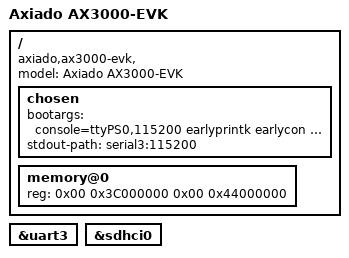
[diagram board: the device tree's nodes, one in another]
// SPDX-License-Identifier: GPL-2.0+
/*
 * Copyright (c) 2021-25 Axiado Corporation (or its affiliates).
 */

/dts-v1/;

#include "ax3000.dtsi"

/ {
	model = "Axiado AX3000-EVK";
	compatible = "axiado,ax3000-evk,", "axiado, ax3000";
	#address-cells = <2>;
	#size-cells = <2>;

	chosen {
		bootargs = "console=ttyPS0,115200 earlyprintk earlycon nr_cpus=4 maxcpus=4";
		stdout-path = "serial3:115200";
	};

	memory@0 {
		device_type = "memory";
		reg = <0x00 0x3C000000 0x00 0x44000000>;
	};
};

&uart3 {
	status = "okay";
};

&sdhci0 {
	status = "okay";
};
